AUTOSAR XML (schema 3-2-1)
package /SeatHeater/SeatHeater_swc
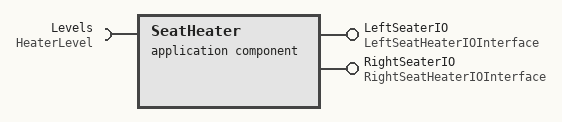
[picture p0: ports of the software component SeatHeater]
  application software component type SeatHeater
    require port Levels: provided-com-specs=[{data-element=LeftHeatLevel, alive-timeout=60.0}, {data-element=RightHeatLevel, alive-timeout=60.0}], provided-interface=HeaterLevel
    provide port LeftSeaterIO: unqueued-provider-com-spec{data-element=LeftHeaterValue, alive-timeout=60.0}, provided-interface=LeftSeatHeaterIOInterface
    provide port RightSeaterIO: unqueued-provider-com-spec{data-element=RightHeaterValue, alive-timeout=60.0}, provided-interface=RightSeatHeaterIOInterface
  internal behavior SeatHeaterBehavior: compontent=SeatHeater
  swc implementation SeatHeaterImplementation: behavior=SeatHeaterBehavior
